# mcr_es17 register map
Registers are access not given, no defined reset value unless marked. A register's access mark holds for its fields unless they carry their own. Offsets are from the block's base; lines under a group give offsets from that group; [hi:lo] are bit positions; {n}, {i} and the like mark numbered series; 'fields as' and 'values as' point back to an identical list; <NAME> marks a mode.

## Memory map
0x40006C00 MCR size 0x400 — Misc Control.

## MCR — Misc Control.
Base 0x40006C00
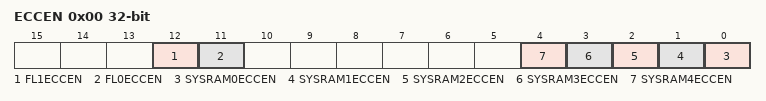
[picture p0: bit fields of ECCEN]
0x00 ECCEN — ECC Enable Register
  [all] fields
    0=dis (disabled.); 1=en (enabled.)
  [12] FL1ECCEN — Flash1 ECC Enable.
  [11] FL0ECCEN — Flash0 ECC Enable.
  [n] SYSRAM{n}ECCEN (n=0..4) — ECC System RAM Enable.
